AUTOSAR XML (schema 4-2-2)
package /PWCR
  sender receiver interface VePWCR_b_CrashDetected
    data DataElements_VariableDataPrototype_0: type=Boolean
  sender receiver interface VePWCR_b_SignalFault
    data DataElements_VariableDataPrototype_0: type=Boolean
  sender receiver interface VePWCR_y_RawSignalValue
    data DataElements_VariableDataPrototype_0: type=float32
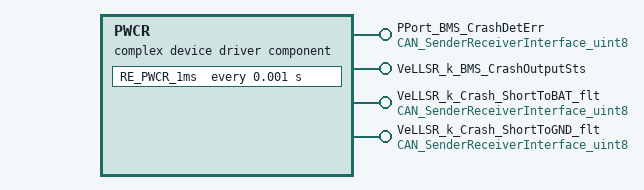
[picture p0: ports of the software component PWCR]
  complex device driver sw component type PWCR
    4 x provide port:
      PPort_BMS_CrashDetErr: provided-interface=CAN_SenderReceiverInterface_uint8
      VeLLSR_k_BMS_CrashOutputSts: provided-interface=VeLLSR_k_BMS_CrashOutputSts
      VeLLSR_k_Crash_ShortToBAT_flt: provided-interface=CAN_SenderReceiverInterface_uint8
      VeLLSR_k_Crash_ShortToGND_flt: provided-interface=CAN_SenderReceiverInterface_uint8
    behavior IB_PWCR: data-type-mapping=DHSR_CodeDataTypeMappingsSet
      timing event TimingEvent_PWCR_1ms: start-on-event=RE_PWCR_1ms, period=0.001
      runnable RE_PWCR_1ms
        data-write-access:
          4 x access:
            DWA_uint8_0: accessed-variable=VeLLSR_k_Crash_ShortToGND_flt.uint8
            DWA_uint8_1: accessed-variable=VeLLSR_k_Crash_ShortToBAT_flt.uint8
            DWA_uint8_2: accessed-variable=PPort_BMS_CrashDetErr.uint8
            DWA_uint8_3: accessed-variable=VeLLSR_k_BMS_CrashOutputSts.VeLLSR_k_BMS_CrashOutputSts
